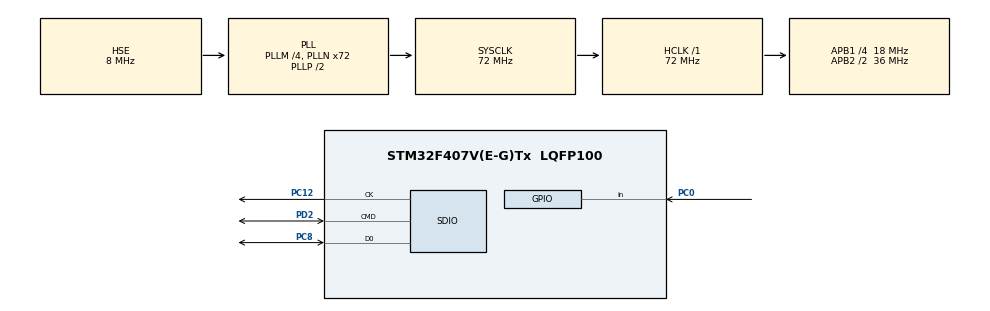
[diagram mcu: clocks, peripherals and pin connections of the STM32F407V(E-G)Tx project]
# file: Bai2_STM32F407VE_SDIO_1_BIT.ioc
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Mcu.Family=STM32F4
RCC.PLLSourceVirtual=RCC_PLLSOURCE_HSE
FATFS0.BSP.STBoard=false
PH0-OSC_IN.Signal=RCC_OSC_IN
RCC.CortexFreq_Value=72000000
FATFS0.BSP.api=Unknown
VP_FATFS_VS_SDIO.Mode=SDIO
PC12.Signal=SDIO_CK
FATFS0.BSP.mode=Input
PC8.Signal=SDIO_D0
PC0.Signal=GPIO_Input
RCC.APB1CLKDivider=RCC_HCLK_DIV4
NVIC.SDIO_IRQn=true\:0\:0\:false\:false\:true\:true\:true
RCC.SYSCLKSource=RCC_SYSCLKSOURCE_PLLCLK
ProjectManager.StackSize=0x400
FATFS0.BSP.instance=PC0
PA13.Signal=SYS_JTMS-SWDIO
ProjectManager.TargetToolchain=MDK-ARM V5
RCC.HCLKFreq_Value=72000000
RCC.APB2TimFreq_Value=72000000
RCC.LSE_VALUE=32768
RCC.AHBFreq_Value=72000000
PH0-OSC_IN.Mode=HSE-External-Oscillator
FATFS0.BSP.ip=GPIO
FATFS.BSP.number=1
PD2.Mode=SD_1_bit
RCC.HSE_VALUE=8000000
PC12.Mode=SD_1_bit
FATFS0.BSP.i2caddr=0
board=custom
RCC.VCOOutputFreq_Value=144000000
FATFS._USE_STRFUNC=2
RCC.APB2Freq_Value=36000000
PA14.Mode=Serial_Wire
PH1-OSC_OUT.Signal=RCC_OSC_OUT
PA13.Mode=Serial_Wire
Mcu.Name=STM32F407V(E-G)Tx
PC8.Mode=SD_1_bit
PH1-OSC_OUT.Mode=HSE-External-Oscillator
RCC.48MHZClocksFreq_Value=48000000
RCC.SYSCLKFreq_VALUE=72000000
Mcu.Package=LQFP100
FATFS0.BSP.solution=PC0
PA14.Signal=SYS_JTCK-SWCLK
ProjectManager.HeapSize=0x200
RCC.HSI_VALUE=16000000
RCC.PLLQ=3
NVIC.PriorityGroup=NVIC_PRIORITYGROUP_4
RCC.APB2CLKDivider=RCC_HCLK_DIV2
RCC.PLLM=4
RCC.PLLN=72
RCC.APB1TimFreq_Value=36000000
PD2.Signal=SDIO_CMD
RCC.APB1Freq_Value=18000000
FATFS0.BSP.name=Detect_SDIO

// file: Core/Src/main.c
/* USER CODE BEGIN Header */
/**
  ******************************************************************************
  * @file           : main.c
  * @brief          : Main program body
  ******************************************************************************
  * @attention
  *
  * <h2><center>&copy; Copyright (c) 2022 STMicroelectronics.
  * All rights reserved.</center></h2>
  *
  * This software component is licensed by ST under Ultimate Liberty license
  * SLA0044, the "License"; You may not use this file except in compliance with
  * the License. You may obtain a copy of the License at:
  *                             www.st.com/SLA0044
  *
  ******************************************************************************
  */
/* USER CODE END Header */
#include "main.h"
#include "fatfs.h"

SD_HandleTypeDef hsd;

/* USER CODE BEGIN PV */
FATFS fatfs;
FIL myfile;
FRESULT fresult;

uint8_t recive_arr[100];
uint8_t byte_read = 0;
/* USER CODE END PV */

void SystemClock_Config(void);
static void MX_GPIO_Init(void);
static void MX_SDIO_SD_Init(void);

int main(void)
{

  /* MCU Configuration--------------------------------------------------------*/

  /* Reset of all peripherals, Initializes the Flash interface and the Systick. */
  HAL_Init();

  /* Configure the system clock */
  SystemClock_Config();

  /* Initialize all configured peripherals */
  MX_GPIO_Init();
  MX_SDIO_SD_Init();
  MX_FATFS_Init();
  /* USER CODE BEGIN 2 */
	//ghi du lieu vao the
	if(BSP_SD_Init() == MSD_OK)
	{
		fresult = f_mount(&fatfs, "", 1);
		fresult = f_open(&myfile, "sdiotest.txt", FA_CREATE_ALWAYS|FA_WRITE);
		f_printf(&myfile, "khue nguyen creator\n");
		f_close(&myfile);
	}

	//doc du lieu the nho
//	if(BSP_SD_Init() == MSD_OK)
//	{
//		fresult = f_mount(&fatfs, "", 1);
//		fresult = f_open(&myfile, "sdiotest.txt",FA_READ);
//		fresult = f_read(&myfile, &recive_arr, f_size(&myfile), (UINT*)&byte_read);
//		f_close(&myfile);
//	}
  /* USER CODE END 2 */

  /* Infinite loop */
  while (1)
  {

  }
}

void SystemClock_Config(void)
{
  RCC_OscInitTypeDef RCC_OscInitStruct = {0};
  RCC_ClkInitTypeDef RCC_ClkInitStruct = {0};

  /** Configure the main internal regulator output voltage
  */
  __HAL_RCC_PWR_CLK_ENABLE();
  __HAL_PWR_VOLTAGESCALING_CONFIG(PWR_REGULATOR_VOLTAGE_SCALE1);
  /** Initializes the RCC Oscillators according to the specified parameters
  * in the RCC_OscInitTypeDef structure.
  */
  RCC_OscInitStruct.OscillatorType = RCC_OSCILLATORTYPE_HSE;
  RCC_OscInitStruct.HSEState = RCC_HSE_ON;
  RCC_OscInitStruct.PLL.PLLState = RCC_PLL_ON;
  RCC_OscInitStruct.PLL.PLLSource = RCC_PLLSOURCE_HSE;
  RCC_OscInitStruct.PLL.PLLM = 4;
  RCC_OscInitStruct.PLL.PLLN = 72;
  RCC_OscInitStruct.PLL.PLLP = RCC_PLLP_DIV2;
  RCC_OscInitStruct.PLL.PLLQ = 3;
  if (HAL_RCC_OscConfig(&RCC_OscInitStruct) != HAL_OK)
  {
    Error_Handler();
  }
  /** Initializes the CPU, AHB and APB buses clocks
  */
  RCC_ClkInitStruct.ClockType = RCC_CLOCKTYPE_HCLK|RCC_CLOCKTYPE_SYSCLK
                              |RCC_CLOCKTYPE_PCLK1|RCC_CLOCKTYPE_PCLK2;
  RCC_ClkInitStruct.SYSCLKSource = RCC_SYSCLKSOURCE_PLLCLK;
  RCC_ClkInitStruct.AHBCLKDivider = RCC_SYSCLK_DIV1;
  RCC_ClkInitStruct.APB1CLKDivider = RCC_HCLK_DIV4;
  RCC_ClkInitStruct.APB2CLKDivider = RCC_HCLK_DIV2;

  if (HAL_RCC_ClockConfig(&RCC_ClkInitStruct, FLASH_LATENCY_2) != HAL_OK)
  {
    Error_Handler();
  }
}

static void MX_SDIO_SD_Init(void)
{

  hsd.Instance = SDIO;
  hsd.Init.ClockEdge = SDIO_CLOCK_EDGE_RISING;
  hsd.Init.ClockBypass = SDIO_CLOCK_BYPASS_DISABLE;
  hsd.Init.ClockPowerSave = SDIO_CLOCK_POWER_SAVE_DISABLE;
  hsd.Init.BusWide = SDIO_BUS_WIDE_1B;
  hsd.Init.HardwareFlowControl = SDIO_HARDWARE_FLOW_CONTROL_DISABLE;
  hsd.Init.ClockDiv = 0;

}

static void MX_GPIO_Init(void)
{

  /* GPIO Ports Clock Enable */
  __HAL_RCC_GPIOH_CLK_ENABLE();
  __HAL_RCC_GPIOC_CLK_ENABLE();
  __HAL_RCC_GPIOA_CLK_ENABLE();
  __HAL_RCC_GPIOD_CLK_ENABLE();

}

void Error_Handler(void)
{
  __disable_irq();
  while (1)
  {
  }
}

/************************ (C) COPYRIGHT STMicroelectronics *****END OF FILE****/
